AUTOSAR XML (schema 00048)
package /ComponentTypes
  swc implementation Gyro_Implementation: behavior=Gyro_InternalBehavior
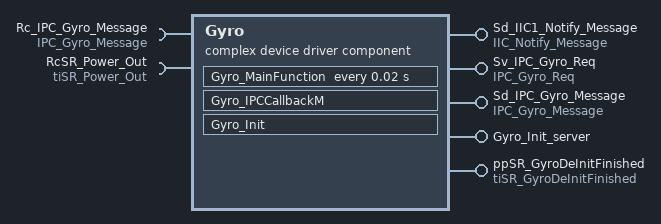
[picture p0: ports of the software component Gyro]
  complex device driver sw component type Gyro
    provide port Sd_IIC1_Notify_Message: queued-sender-com-spec=Message, provided-interface=IIC_Notify_Message
    provide port Sv_IPC_Gyro_Req: server-com-spec{operation=Operation, queue-length=1}, provided-interface=IPC_Gyro_Req
    provide port Sd_IPC_Gyro_Message: queued-sender-com-spec=Element, provided-interface=IPC_Gyro_Message
    require port Rc_IPC_Gyro_Message: queued-receiver-com-spec{data-element=Element, queue-length=10}, required-interface=IPC_Gyro_Message
    provide port Gyro_Init_server: server-com-spec{operation=Operation, queue-length=1}, provided-interface=Gyro_Init_server
    provide port ppSR_GyroDeInitFinished: nonqueued-sender-com-spec{data-element=State, init-value=0}, provided-interface=tiSR_GyroDeInitFinished
    require port RcSR_Power_Out: nonqueued-receiver-com-spec{data-element=SystemStateOut, filter=data-filter-type=ALWAYS, init-value=constant-reference=PowerOutInit}, required-interface=tiSR_Power_Out
    behavior Gyro_InternalBehavior: port-api-option{enable-take-address=true, error-handling=NO-TRANSFORMER-ERROR-HANDLING, indirect-api=false, port=Gyro_Init_server}
      exclusive area ExclusiveArea_Gyro
      timing event TMT_Gyro_MainFunction: start-on-event=Gyro_MainFunction, period=0.02
      operation invoked event OIT_Sv_IPC_Gyro_Req_Operation_Sv_IPC_Gyro_Req_Operation: start-on-event=Gyro_IPCCallbackM, operation=Sv_IPC_Gyro_Req.Operation
      operation invoked event OIT_Gyro_Init_server_Operation_Gyro_Init_server_Operation: start-on-event=Gyro_Init, operation=Gyro_Init_server.Operation
      runnable Gyro_MainFunction: can-enter-exclusive-area=ExclusiveArea_Gyro
        data-receive-point-by-arguments:
          access REC_Rc_IPC_Gyro_Message_Element: accessed-variable=Rc_IPC_Gyro_Message.Element
          access REC_RcSR_Power_Out_SystemStateOut: accessed-variable=RcSR_Power_Out.SystemStateOut
        data-send-points:
          access SEND_Sd_IIC1_Notify_Message_Message: accessed-variable=Sd_IIC1_Notify_Message.Message
          access SEND_ppSR_GyroDeInitFinished_State: accessed-variable=ppSR_GyroDeInitFinished.State
      runnable Gyro_IPCCallbackM
        data-send-points:
          access SEND_Sd_IPC_Gyro_Message_Element: accessed-variable=Sd_IPC_Gyro_Message.Element
      runnable Gyro_Init
